# DSPIC33FJ128MC804 register map
Vendor: Microchip
Registers are 16-bit, read-write, reset 0x0 unless marked. A register's access mark holds for its fields unless they carry their own. Addresses are absolute, and some are shared; only a register's first bit layout is shown; [hi:lo] are bit positions; {n}, {i} and the like mark numbered series.

## CONFIG — Configuration words, addresses in ProgramSpace
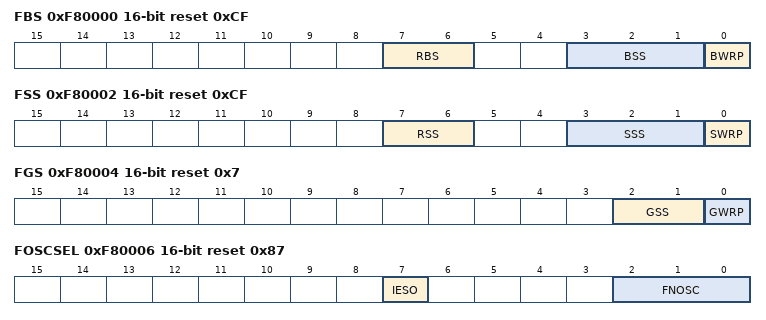
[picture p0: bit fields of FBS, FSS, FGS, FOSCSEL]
0xF80000 FBS reset 0xCF
  [7:6] RBS — Boot Segment RAM Protection
    3=NO_RAM (No Boot RAM); 3=NO_BOOT_RAM; 2=SMALL_RAM (Small-sized Boot RAM); 2=SMALL_BOOT_RAM (Small-sized Boot RAM); 1=MEDIUM_RAM (Medium-sized Boot RAM); 1=MEDIUM_BOOT_RAM (Medium-sized Boot RAM); 0=LARGE_RAM (Large-sized Boot RAM); 0=LARGE_BOOT_RAM (Large-sized Boot RAM)
  [3:1] BSS — Boot Segment Program Flash Code Protection
    7=NO_FLASH (No Boot program Flash segment); 7=NO_BOOT_CODE (No Boot program Flash segment); 6=SMALL_FLASH_STD (Standard Security, Small-sized Boot Flash); 6=STRD_SMALL_BOOT_CODE (Standard Security, Small-sized Boot Flash); 5=MEDIUM_FLASH_STD (Standard Security, Medium-sized Boot Flash); 5=STRD_MEDIUM_BOOT_CODE (Standard Security, Medium-sized Boot Flash); 4=LARGE_FLASH_STD (Standard Security, Large-sized Boot Flash); 4=STRD_LARGE_BOOT_CODE (Standard Security, Large-sized Boot Flash); 3=No Boot program Flash segment; 2=SMALL_FLASH_HIGH (High Security, Small-sized Boot Flash); 2=HIGH_SMALL_BOOT_CODE (High Security, Small-sized Boot Flash); 1=MEDIUM_FLASH_HIGH (High Security, Medium-sized Boot Flash); 1=HIGH_MEDIUM_BOOT_CODE (High Security, Medium-sized Boot Flash); 0=LARGE_FLASH_HIGH (High Security, Large-sized Boot Flash); 0=HIGH_LARGE_BOOT_CODE (High Security, Large-sized Boot Flash)
  [0] BWRP — Boot Segment Write Protect
    1=WRPROTECT_OFF (Boot Segment may be written); 0=WRPROTECT_ON (Boot segment is write-protected)
0xF80002 FSS reset 0xCF
  [7:6] RSS — Secure Segment Data RAM Protection
    3=NO_RAM (No Secure RAM); 3=NO_SEC_RAM (No Secure RAM); 2=SMALL_RAM (Small-sized Secure RAM); 2=SMALL_SEC_RAM (Small-sized Secure RAM); 1=MEDIUM_RAM (Medium-sized Secure RAM); 1=MEDIUM_SEC_RAM (Medium-sized Secure RAM); 0=LARGE_RAM (Large-sized Secure RAM); 0=LARGE_SEC_RAM (Large-sized Secure RAM)
  [3:1] SSS — Secure Segment Program Flash Code Protection
    7=NO_FLASH (No Secure Segment); 7=NO_SEC_CODE (No Secure Segment); 6=SMALL_FLASH_STD (Standard Security, Small-sized Secure Flash); 6=STRD_SMALL_SEC_CODE (Standard Security, Small-sized Secure Flash); 5=MEDIUM_FLASH_STD (Standard Security, Medium-sized Secure Flash); 5=STRD_MEDIUM_SEC_CODE (Standard Security, Medium-sized Secure Flash); 4=LARGE_FLASH_STD (Standard Security, Large-sized Secure Flash); 4=STRD_LARGE_SEC_CODE (Standard Security, Large-sized Secure Flash); 3=No Secure Segment; 2=SMALL_FLASH_HIGH (High Security, Small-sized Secure Flash); 2=HIGH_SMALL_SEC_CODE (High Security, Small-sized Secure Flash); 1=MEDIUM_FLASH_HIGH (High Security, Medium-sized Secure Flash); 1=HIGH_MEDIUM_SEC_CODE (High Security, Medium-sized Secure Flash); 0=LARGE_FLASH_HIGH (High Security, Large-sized Secure Flash); 0=HIGH_LARGE_SEC_CODE (High Security, Large-sized Secure Flash)
  [0] SWRP — Secure Segment Program Write Protect
    1=WRPROTECT_OFF (Secure segment may be written); 0=WRPROTECT_ON (Secure segment is write-protected)
0xF80004 FGS reset 0x7
  [2:1] GSS — General Segment Code Protection
    3=OFF (User program memory is not code-protected); 2=ON (Standard Security Code Protection is Enabled); 1=HIGH (High Security Code Protection is Enabled)
  [0] GWRP — General Code Segment Write Protect
    1=OFF (User program memory is not write-protected); 0=ON (User program memory is write-protected)
0xF80006 FOSCSEL reset 0x87
  [7] IESO — Internal External Switch Over Mode
    1=ON (Start-up device with FRC, then automatically switch to user-selected oscillator source when ready); 0=OFF (Start-up device with user-selected oscillator source)
  [2:0] FNOSC — Oscillator Mode
    7=LPRCDIVN (Internal Fast RC (FRC) with divide by N); 6=FRCDIV16 (Internal Fast RC (FRC) divide by 16); 5=LPRC (Low Power RC Oscillator (LPRC)); 4=SOSC (Secondary Oscillator (SOSC)); 3=PRIPLL (Primary Oscillator (XT, HS, EC) w/ PLL); 2=PRI (Primary Oscillator (XT, HS, EC)); 1=FRCPLL (Internal Fast RC (FRC) w/ PLL); 0=FRC (Internal Fast RC (FRC))
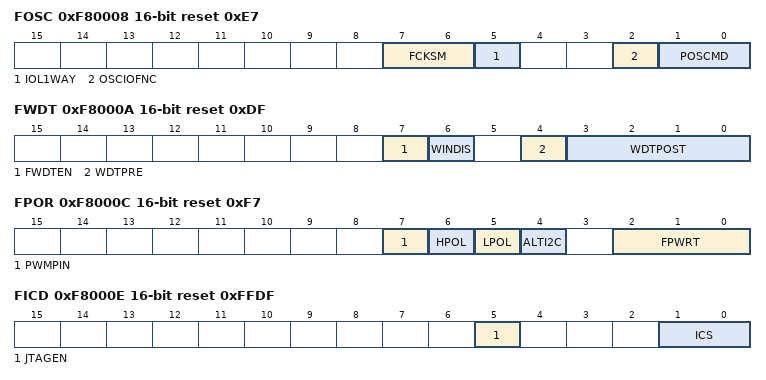
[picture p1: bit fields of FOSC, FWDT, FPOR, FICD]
0xF80008 FOSC reset 0xE7
  [7:6] FCKSM — Clock Switching and Monitor
    0b1x=CSDCMD (Both Clock Switching and Fail-Safe Clock Monitor are disabled); 1=CSECMD (Clock switching is enabled, Fail-Safe Clock Monitor is disabled); 0=CSECME (Both Clock Switching and Fail-Safe Clock Monitor are enabled)
  [5] IOL1WAY — Peripheral Pin Select Configuration
    1=ON (Allow Only One Re-configuration); 0=OFF (Allow Multiple Re-configurations)
  [2] OSCIOFNC — OSC2 Pin Function
    1=OFF (OSC2 pin has clock out function); 0=ON (OSC2 pin has digital I/O function)
  [1:0] POSCMD — Primary Oscillator Source
    3=NONE (Primary Oscillator Disabled); 2=HS (HS Oscillator Mode); 1=XT (XT Oscillator Mode); 0=EC (EC Oscillator Mode)
0xF8000A FWDT reset 0xDF
  [7] FWDTEN — Watchdog Timer Enable
    1=ON (Watchdog timer always enabled); 0=OFF (Watchdog timer enabled/disabled by user software)
  [6] WINDIS — Watchdog Timer Window
    1=OFF (Watchdog Timer in Non-Window mode); 0=ON (Watchdog Timer in Window mode)
  [4] WDTPRE — WDT Prescaler
    1=PR128 (1:128); 0=PR32 (1:32)
  [3:0] WDTPOST — Watchdog Timer Postscaler
    15=PS32768 (1:32,768); 14=PS16384 (1:16,384); 13=PS8192 (1:8,192); 12=PS4096 (1:4,096); 11=PS2048 (1:2,048); 10=PS1024 (1:1,024); 9=PS512 (1:512); 8=PS256 (1:256); 7=PS128 (1:128); 6=PS64 (1:64); 5=PS32 (1:32); 4=PS16 (1:16); 3=PS8 (1:8); 2=PS4 (1:4); 1=PS2 (1:2); 0=PS1 (1:1)
0xF8000C FPOR reset 0xF7
  [7] PWMPIN — Motor Control PWM Module Pin Mode bit
    1=ON (PWM module pins controlled by PORT register at device Reset); 0=OFF (PWM module pins controlled by PWM module at device Reset)
  [6] HPOL — Motor Control PWM High Side Polarity bit
    1=ON (PWM module high side output pins have active-high output polarity); 0=OFF (PWM module high side output pins have active-low output polarity)
  [5] LPOL — Motor Control PWM Low Side Polarity bit
    1=ON (PWM module low side output pins have active-high output polarity); 0=OFF (PWM module low side output pins have active-low output polarity)
  [4] ALTI2C — Alternate I2C pins
    1=OFF (I2C mapped to SDA1/SCL1 pins); 0=ON (I2C mapped to ASDA1/ASCL1 pins)
  [2:0] FPWRT — POR Timer Value
    7=PWR128 (128ms); 6=PWR64 (64ms); 5=PWR32 (32ms); 4=PWR16 (16ms); 3=PWR8 (8ms); 2=PWR4 (4ms); 1=PWR2 (2ms); 0=PWR1 (Disabled)
0xF8000E FICD reset 0xFFDF
  [5] JTAGEN — JTAG Port Enable
    1=ON (JTAG is Enabled); 0=OFF (JTAG is Disabled)
  [1:0] ICS — Comm Channel Select
    3=PGD1 (Communicate on PGC1/EMUC1 and PGD1/EMUD1); 2=PGD2 (Communicate on PGC2/EMUC2 and PGD2/EMUD2); 1=PGD3 (Communicate on PGC3/EMUC3 and PGD3/EMUD3)
{0xF80010+2i} FUID{i} reset 0xFFFF (i=0..3)
  [7:0] UID{i}
